# APM32F41x register map
File version: 1.0
CPU: CM4 r1p0, little endian, no MPU, no FPU, 3 interrupt priority bits
Registers are 32-bit, read-write, reset 0x0 unless marked. A register's access mark holds for its fields unless they carry their own. Offsets are from the block's base; [hi:lo] are bit positions; {n}, {i} and the like mark numbered series.

## Ethernet_MAC — Ethernet: media access control (MAC)
Base 0x40028000
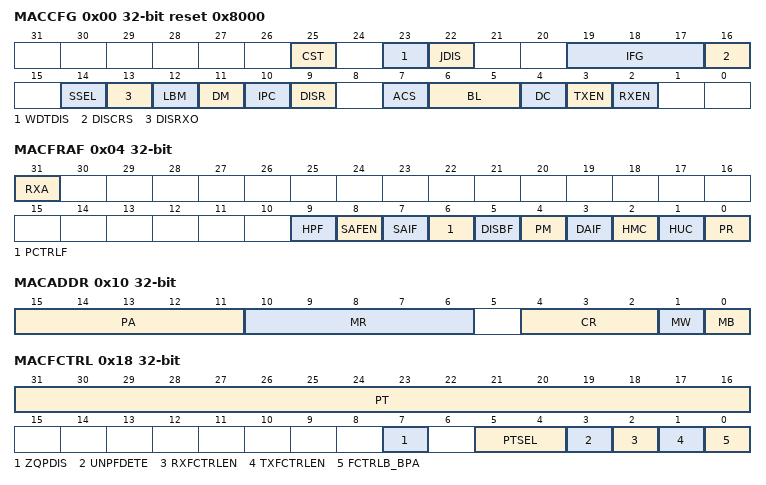
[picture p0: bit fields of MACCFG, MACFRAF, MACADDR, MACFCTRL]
0x00 MACCFG reset 0x8000 — Ethernet MAC configuration register
  [25] CST — CRC Stripping for Type Frames
  [23] WDTDIS — Watchdog Disable
  [22] JDIS — Jabber Disable
  [19:17] IFG — Inter-Frame Gap
  [16] DISCRS — Disable Carrier Sense During Transmission
  [14] SSEL — Speed
  [13] DISRXO — Disable Receive Own
  [12] LBM — Loopback Mode
  [11] DM — Duplex Mode
  [10] IPC — IPv4 Checksum offload
  [9] DISR — Disable Retry
  [7] ACS — Automatic Pad or CRC Stripping
  [6:5] BL — Back off Limit
  [4] DC — Deferral Check
  [3] TXEN — Transmitter Enable
  [2] RXEN — Receiver Enable
0x04 MACFRAF — Ethernet MAC frame filter register
  [31] RXA — Receive All
  [9] HPF — Hash or Perfect Filter
  [8] SAFEN — Source Address Filter Enable
  [7] SAIF — SA Inverse Filtering
  [6] PCTRLF — Pass Control Frames
  [5] DISBF — Disable Broadcast Frames
  [4] PM — Pass All Multicast
  [3] DAIF — DA Inverse Filtering
  [2] HMC — Hash Multicast
  [1] HUC — Hash Unicast
  [0] PR — Promiscuous Mode
0x08 MACHTH — Ethernet MAC hash table high register
  [31:0] HTH — Hash Table High
0x0C MACHTL — Ethernet MAC hash table low register
  [31:0] HTL — Hash Table Low
0x10 MACADDR — Ethernet MAC MII address register
  [15:11] PA — Physical Layer Address
  [10:6] MR — MII Register
  [4:2] CR — Clock Range
  [1] MW — MII Write
  [0] MB — MII Busy
0x14 MACDATA — Ethernet MAC MII data register
  [15:0] MD — MII Data
0x18 MACFCTRL — Ethernet MAC flow control register
  [31:16] PT — Pause Time
  [7] ZQPDIS — Zero-quanta Pause Disable
  [5:4] PTSEL — Pause Threshold Select
  [3] UNPFDETE — Unicast Pause Frame Detect
  [2] RXFCTRLEN — Receive Flow Control Enable
  [1] TXFCTRLEN — Transmit Flow Control Enable
  [0] FCTRLB_BPA — Flow Control Busy/Back Pressure Activate
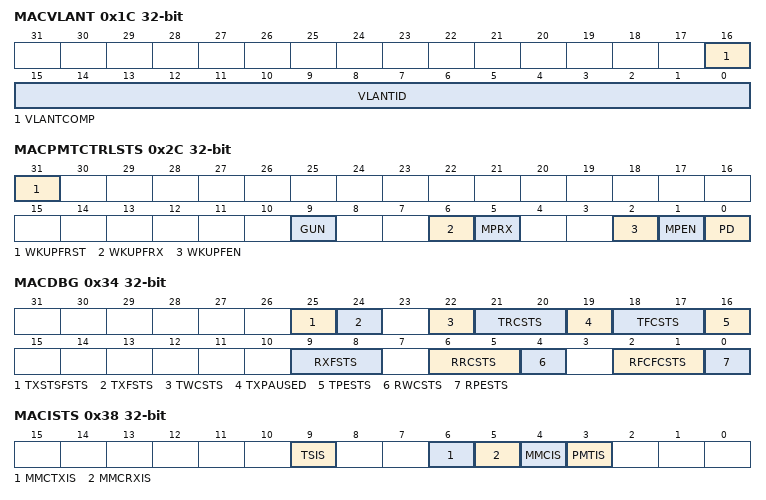
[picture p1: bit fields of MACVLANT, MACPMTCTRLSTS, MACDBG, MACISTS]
0x1C MACVLANT — Ethernet MAC VLAN tag register
  [16] VLANTCOMP — 12-bit VLAN Tag Comparison
  [15:0] VLANTID — VLAN Tag Identifier
0x2C MACPMTCTRLSTS — Ethernet MAC PMT control and status register
  [31] WKUPFRST — Wakeup Frame Filter Register Pointer Reset
  [9] GUN — Global Unicast
  [6] WKUPFRX — Wakeup Frame Received
  [5] MPRX — Magic Packet Received
  [2] WKUPFEN — Wakeup Frame Enable
  [1] MPEN — Magic Packet Enable
  [0] PD — Power Down
0x34 MACDBG ro — Ethernet MAC debug register
  [25] TXSTSFSTS — TX Status FIFO Full Status
  [24] TXFSTS — TX FIFO Not Empty Status
  [22] TWCSTS — TX FIFO Write Controller Status
  [21:20] TRCSTS — TX FIFO Read Controller Status
  [19] TXPAUSED — MAC Transmitter in Pause
  [18:17] TFCSTS — MAC Transmit Frame Controller Status
  [16] TPESTS — MAC MII Transmit Protocol Engine Status
  [9:8] RXFSTS — RX FIFO full - level Status
  [6:5] RRCSTS — RX FIFO Read Controller State
  [4] RWCSTS — RX FIFO Write Controller Active Status
  [2:1] RFCFCSTS — MAC Receive Frame FIFO Controller Status
  [0] RPESTS — MAC MII Receive Protocol Engine Status
0x38 MACISTS access per field — Ethernet MAC interrupt status register
  [9] TSIS rw — Timestamp Interrupt Status
  [6] MMCTXIS ro — MMC Transmit Interrupt Status
  [5] MMCRXIS ro — MMC Receive Interrupt Status
  [4] MMCIS ro — MMC Interrupt Status
  [3] PMTIS ro — PMT Interrupt Status
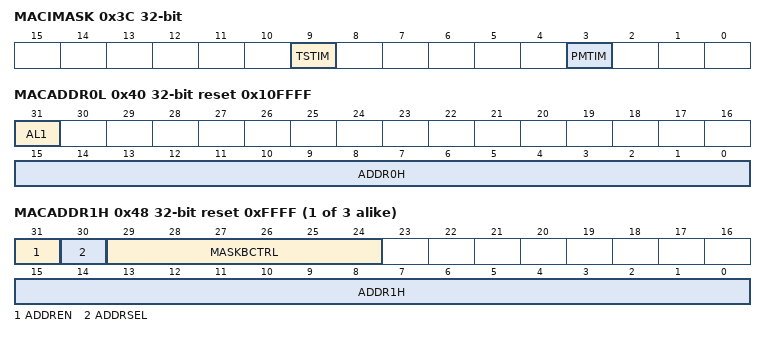
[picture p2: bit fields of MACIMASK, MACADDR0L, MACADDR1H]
0x3C MACIMASK — Ethernet MAC interrupt mask register
  [9] TSTIM — Time Stamp Trigger Interrupt Mask
  [3] PMTIM — PMT Interrupt Mask
0x40 MACADDR0L access per field reset 0x10FFFF — Ethernet MAC address 0 high register
  [31] AL1 ro — Always 1
  [15:0] ADDR0H rw — MAC address0 high
0x44 MACMACA0LR reset 0xFFFFFFFF — Ethernet MAC address 0 low register
  [31:0] ADDR0L — MAC Address 0
{0x40+8i} MACADDR{i}H reset 0xFFFF (i=1..3) — Ethernet MAC address {i} high register
  [31] ADDREN — Address Enable
  [30] ADDRSEL — Address Select
  [29:24] MASKBCTRL — Mask Byte Control
  [15:0] ADDR{i}H — MAC Address {i}
0x4C MACADDR1L reset 0xFFFFFFFF — Ethernet MAC address1 low register
  [31:0] ADDR1L — MAC Address 1
0x54 MACADDR2L reset 0xFFFFFFFF — Ethernet MAC address 2 low register
  [30:0] ADDR2L — MAC Address 2
0x5C MACADDR3L reset 0xFFFFFFFF — Ethernet MAC address 3 low register
  [31:0] ADDR3L — MAC Address 3
